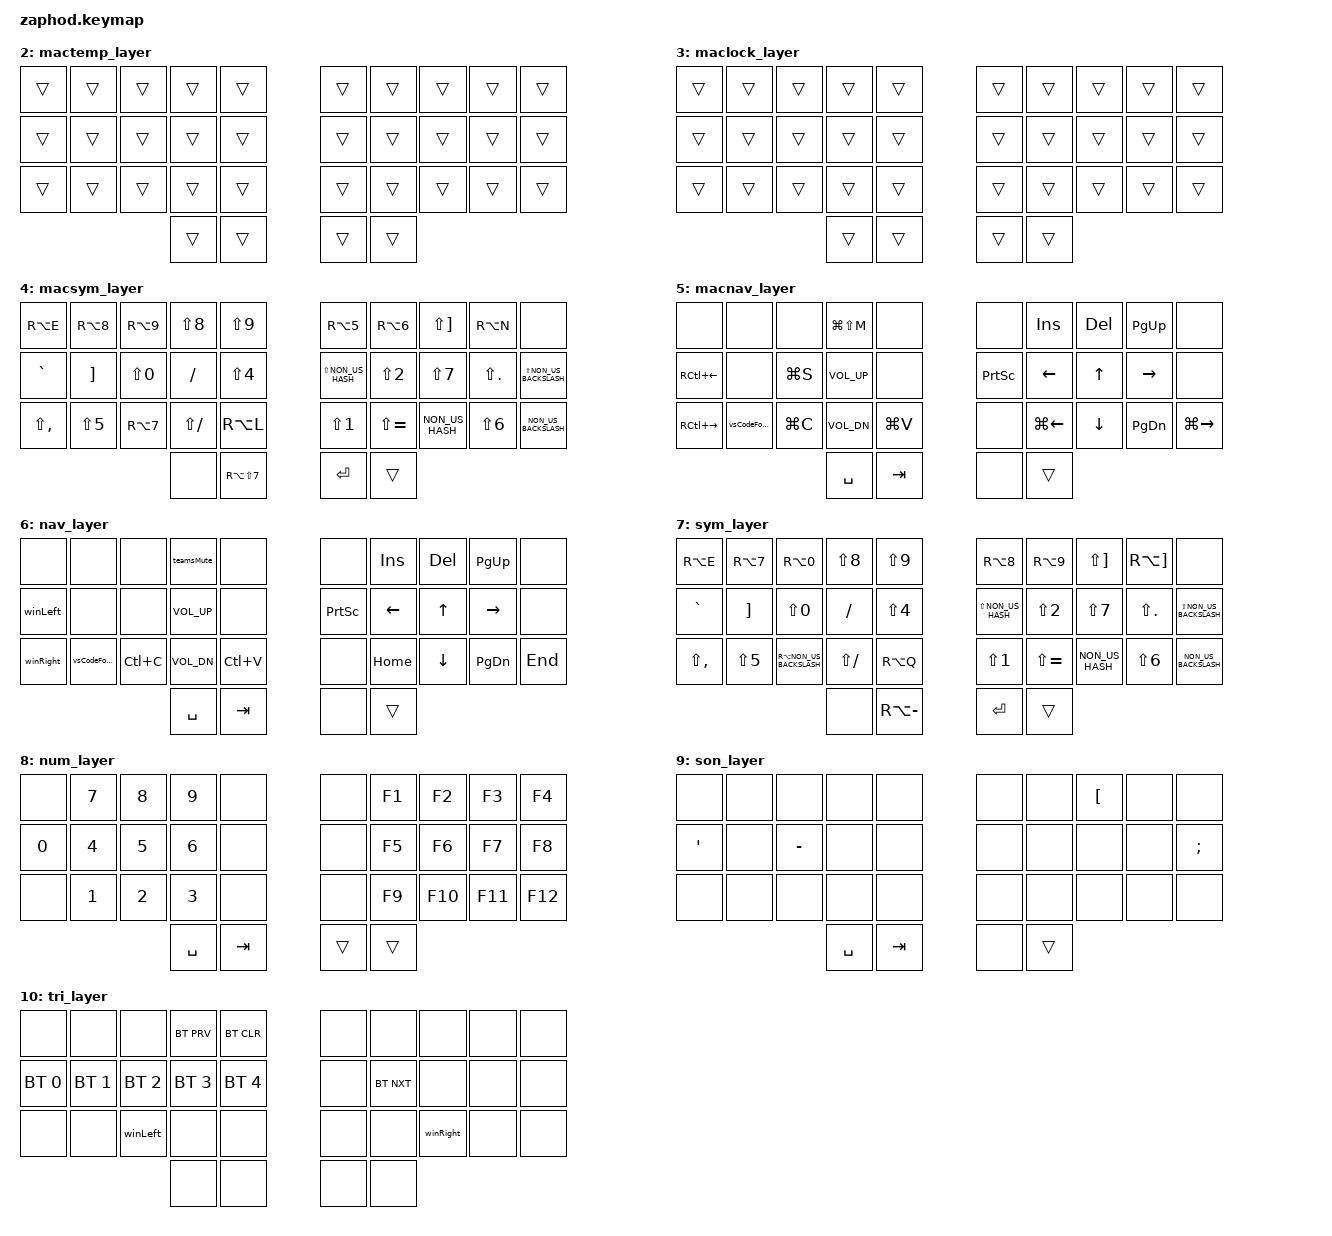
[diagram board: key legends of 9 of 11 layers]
/*
 * Copyright (c) 2022 The ZMK Contributors
 *
 * SPDX-License-Identifier: MIT
 */

#include <behaviors.dtsi>
#include <dt-bindings/zmk/keys.h>
#include <dt-bindings/zmk/bt.h>
#include <dt-bindings/zmk/outputs.h>

#define HRML(k1,k2,k3,k4) &ht LGUI k1  &ht LALT k2  &ht LCTRL k3  &ht LSHIFT k4
#define HMAC(k1,k2,k3,k4) &ht LCTRL k1  &ht LALT k2  &ht LGUI k3  &ht LSHIFT k4
#define AC(keycode) &ac LC(keycode) keycode
#define MC(keycode) &ac LG(keycode) keycode

#define LTR 0
#define MAC 1
#define MACTEMP 2
#define MACLOCK 3
#define MACSYM 4
#define MACNAV 5
#define NAV 6
#define SYM 7
#define NUM 8
#define SON 9
#define TRI 10

&mt {
  //  standard is hold preferred with tapping_term_ms = <200>;
};

/ { 

    combos {
        compatible = "zmk,combos";
        combo_bkspc {
            timeout-ms = <50>;
            key-positions = <26 27>; // H + ,
            bindings = <&kp BACKSPACE>;
        };
        combo_esc {
            timeout-ms = <50>;
            key-positions = <0 1>; // Q + W
            bindings = <&kp ESC>;
        };
        combo_mac1 {
            timeout-ms = <50>;
            key-positions = <5 6>; // Q + W
            bindings = <&mo MACTEMP>;
        };
        combo_mac2 {
            timeout-ms = <50>;
            key-positions = <3 4>; // Q + W
            bindings = <&tog MACLOCK>;
        };
    };

    behaviors {
        ht: hold_tap {
            label = "hold_tap";
            compatible = "zmk,behavior-hold-tap";
            #binding-cells = <2>;
            flavor = "tap-preferred";
            tapping-term-ms = <200>;
            quick-tap-ms = <150>;
            global-quick-tap;
            bindings = <&kp>, <&kp>;
        };
        ac: auto_control {
                compatible = "zmk,behavior-hold-tap";
                label = "AUTO_CONTROL";
                #binding-cells = <2>;
                tapping_term_ms = <200>;
                quick_tap_ms = <0>;
                flavor = "tap-preferred";
                bindings = <&kp>, <&kp>;
        };
    };

    macros {
        winLeft: winLeft {
            label = "winLeft";
            compatible = "zmk,behavior-macro";
            #binding-cells = <0>;
            bindings
                = <&macro_press &kp LCTRL &kp LGUI>
                , <&macro_tap &kp LEFT>
                , <&macro_release &kp LCTRL &kp LGUI>
                ;
        };
        winRight: winRight {
            label = "winRight";
            compatible = "zmk,behavior-macro";
            #binding-cells = <0>;
            bindings
                = <&macro_press &kp LCTRL &kp LGUI>
                , <&macro_tap &kp RIGHT>
                , <&macro_release &kp LCTRL &kp LGUI>
                ;
        };
        vsCodeFormat: vsCodeFormat {
            label = "vsCodeFormat";
            compatible = "zmk,behavior-macro";
            #binding-cells = <0>;
            bindings
                = <&macro_press &kp LSHIFT &kp LALT>
                , <&macro_tap &kp F>
                , <&macro_release &kp LSHIFT &kp LALT>
                ;
        };
        teamsMute: teamsMute {
            label = "teamsMute";
            compatible = "zmk,behavior-macro";
            #binding-cells = <0>;
            bindings
                = <&macro_press &kp LSHIFT &kp LCTRL>
                , <&macro_tap &kp M>
                , <&macro_release &kp LSHIFT &kp LCTRL>
                ;
        };
    };

    conditional_layers {
        compatible = "zmk,conditional-layers";
        tri_layer {
            if-layers = <SYM NUM>;
            then-layer = <TRI>;
        };
        mac_temp {
            if-layers = <MACTEMP>;
            then-layer = <MAC>;
        };
        mac_lock {
            if-layers = <MACLOCK>;
            then-layer = <MAC>;
        };
    };

    keymap {
        compatible = "zmk,keymap";
                
       	default_layer {
		    bindings = <
		//╭──────────┬──────────┬──────────┬──────────┬──────────╮   ╭──────────┬──────────┬──────────┬──────────┬──────────╮
        //│  Q       │  W       │  F       │  P       │  B       │   │  J       │  L       │  U       │  Y       │  '       │
            &kp Q      &kp W      &kp F      &kp P      &kp B          &kp J      &kp L      &kp U      &kp Z      &kp LS(NON_US_HASH)
        //├──────────┼──────────┼──────────┼──────────┼──────────┤   ├──────────┼──────────┼──────────┼──────────┼──────────┤
        //│  A       │  R       │  S       │  T       │  G       │   │  M       │  N       │  E       │  I       │  O       │
        HRML(A,         R,         S,         T)       &kp G          &kp M  &ht RSHIFT N  &ht RCTRL E  &lt SON I  &ht RGUI O
        //├──────────┼──────────┼──────────┼──────────┼──────────┤   ├──────────┼──────────┼──────────┼──────────┼──────────┤
        //│  Z       │  X       │  C       │  D       │  V       │   │  K       │  H       │ , <      │ . >      │ ?        │
            &kp Y      &kp X      AC(C)     &kp D       AC(V)          &kp K      &kp H      &kp COMMA  &kp DOT    &kp LS(MINUS)
        //╰──────────┴──────────┴──────────┼──────────┼──────────┤   ├──────────┼──────────┼──────────┴──────────┴──────────╯
                                        &lt NAV SPACE  &lt NUM TAB   &lt SYM ENTER  &mt LSHIFT BACKSPACE
        //                                 ╰──────────┴──────────╯   ╰──────────┴──────────╯                   
		    >;
		};

        mac_default {
		    bindings = <
		//╭──────────┬──────────┬──────────┬──────────┬──────────╮   ╭──────────┬──────────┬──────────┬──────────┬──────────╮
        //│  Q       │  W       │  F       │  P       │  B       │   │  J       │  L       │  U       │  Y       │  '       │
            &kp Q     &kp W      &kp F      &kp P      &kp B          &kp J      &kp L      &kp U      &kp Z      &kp LS(NON_US_HASH)
        //├──────────┼──────────┼──────────┼──────────┼──────────┤   ├──────────┼──────────┼──────────┼──────────┼──────────┤
        //│  A       │  R       │  S       │  T       │  G       │   │  M       │  N       │  E       │  I       │  O       │
        HMAC(A,         R,         S,         T)       &kp G          &kp M  &ht RSHIFT N  &ht RGUI E  &lt SON I  &ht RCTRL O
        //├──────────┼──────────┼──────────┼──────────┼──────────┤   ├──────────┼──────────┼──────────┼──────────┼──────────┤
        //│  Z       │  X       │  C       │  D       │  V       │   │  K       │  H       │ , <      │ . >      │ ?        │
            &kp Y      &kp X      MC(C)     &kp D       MC(V)          &kp K      &kp H      &kp COMMA  &kp DOT    &kp LS(MINUS)
        //╰──────────┴──────────┴──────────┼──────────┼──────────┤   ├──────────┼──────────┼──────────┴──────────┴──────────╯
                                        &lt MACNAV SPACE  &lt NUM TAB   &lt MACSYM ENTER  &mt LSHIFT BACKSPACE
        //                                 ╰──────────┴──────────╯   ╰──────────┴──────────╯                   
		    >;
		};


        mactemp_layer {
		    bindings = <
		&trans &trans &trans &trans &trans &trans &trans &trans &trans &trans
        &trans &trans &trans &trans &trans &trans &trans &trans &trans &trans
        &trans &trans &trans &trans &trans &trans &trans &trans &trans &trans
        &trans &trans &trans &trans                  
		    >;
		};

        maclock_layer {
            bindings = <
		&trans &trans &trans &trans &trans &trans &trans &trans &trans &trans
        &trans &trans &trans &trans &trans &trans &trans &trans &trans &trans
        &trans &trans &trans &trans &trans &trans &trans &trans &trans &trans
        &trans &trans &trans &trans                  
		    >;
        };

        macsym_layer {
		    bindings = <
		&kp RA(E)  &kp RA(N8) &kp RA(N9)  &kp LS(N8)  &kp LS(N9)    			    &kp RA(N5) &kp RA(N6) &kp LS(RBKT) &kp RA(N) &none 
		&kp GRAVE  &kp RBKT  &kp LS(N0)  &kp SLASH  &kp LS(N4) 			            &kp LS(NON_US_HASH) &kp LS(N2) &kp LS(N7) &kp LS(DOT) &kp LS(NON_US_BACKSLASH)
		&kp LS(COMMA) &kp LS(N5) &kp RA(N7) &kp LS(SLASH) &kp RA(L)   &kp LS(N1) &kp LS(EQUAL) &kp NON_US_HASH &kp LS(N6) &kp NON_US_BACKSLASH
					                    &none   &kp RA(LS(N7))                      &kp ENTER &trans
		    >;
		};

        macnav_layer {
		    bindings = <
		&none &none &none &kp LG(LS(M)) &none		                        &none &kp INS &kp DEL &kp PG_UP  &none 
		&kp RC(LEFT) &none &kp LG(S) &kp C_VOL_UP &none                         &kp PSCRN &kp LEFT  &kp UP &kp RIGHT  &none 
		&kp RC(RIGHT) &vsCodeFormat &kp LG(C) &kp C_VOL_DN &kp LG(V)        &none &kp LG(LEFT) &kp DOWN &kp PG_DN  &kp LG(RIGHT) 
					                &kp SPACE &kp TAB                   &none  &trans  
		    >;
		};
		

       	nav_layer {
		    bindings = <
		&none &none &none &teamsMute &none		                        &none &kp INS &kp DEL &kp PG_UP  &none 
		&winLeft &none &none &kp C_VOL_UP &none                         &kp PSCRN &kp LEFT  &kp UP &kp RIGHT  &none 
		&winRight &vsCodeFormat &kp LC(C) &kp C_VOL_DN &kp LC(V)        &none &kp HOME &kp DOWN &kp PG_DN  &kp END 
					                &kp SPACE &kp TAB                   &none  &trans  
		    >;
		};
		
		sym_layer {
		    bindings = <
		&kp RA(E)  &kp RA(N7) &kp RA(N0)  &kp LS(N8)  &kp LS(N9)    			    &kp RA(N8) &kp RA(N9) &kp LS(RBKT) &kp RA(RBKT) &none 
		&kp GRAVE  &kp RBKT  &kp LS(N0)  &kp SLASH  &kp LS(N4) 			            &kp LS(NON_US_HASH) &kp LS(N2) &kp LS(N7) &kp LS(DOT) &kp LS(NON_US_BACKSLASH)
		&kp LS(COMMA) &kp LS(N5) &kp RA(NON_US_BACKSLASH) &kp LS(SLASH) &kp RA(Q)   &kp LS(N1) &kp LS(EQUAL) &kp NON_US_HASH &kp LS(N6) &kp NON_US_BACKSLASH
					                    &none   &kp RA(MINUS)                       &kp ENTER &trans
		    >;
		};

        num_layer {
		    bindings = <
		&none &kp N7 &kp N8 &kp N9 &none                  			&none &kp F1 &kp F2 &kp F3 &kp F4
		&kp N0 &kp N4 &kp N5 &kp N6 &none 			                &none &kp F5 &kp F6 &kp F7 &kp F8
		&none &kp N1 &kp N2 &kp N3 &none  			                &none &kp F9 &kp F10 &kp F11 &kp F12
					  &kp SPACE &kp TAB                   		    &trans  &trans
		    >;
		};

        son_layer {
		    bindings = <
		&none &none &none &none &none    			        &none &none &kp LBKT &none &none 
		&kp SINGLE_QUOTE &none &kp MINUS &none &none        &none &none &none &none &kp SEMICOLON
		&none &none &none &none &none    			        &none &none &none &none &none
                    &kp SPACE &kp TAB   			        &none  &trans
		    >;
		};	
		
		tri_layer {
		    bindings = <
		&none &none &none &bt BT_PRV &bt BT_CLR			                        &none &none &none &none &none
		&bt BT_SEL 0 &bt BT_SEL 1  &bt BT_SEL 2 &bt BT_SEL 3 &bt BT_SEL 4  		&none &bt BT_NXT &none &none &none 
		&none &none &winLeft &none &none   				                        &none &none &winRight &none &none
					        &none &none  					                    &none &none 
		    >;
		};	
        
	};
};
